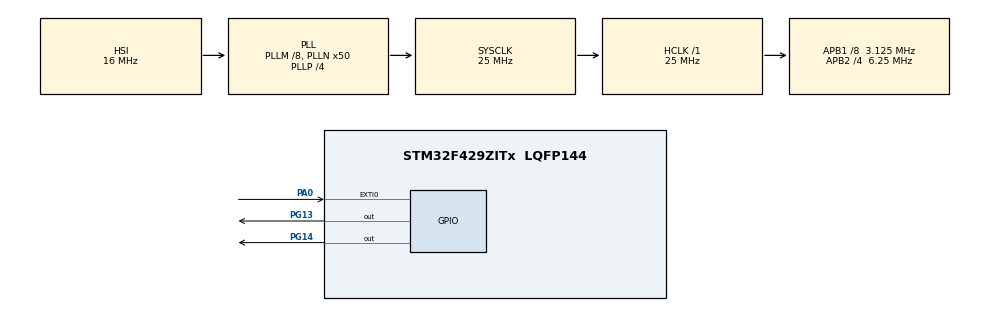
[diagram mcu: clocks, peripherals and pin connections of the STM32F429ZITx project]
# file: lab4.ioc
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Mcu.Family=STM32F4
Mcu.Name=STM32F429ZITx
Mcu.Package=LQFP144
NVIC.EXTI0_IRQn=true\:0\:0\:false\:false\:true\:true\:true\:true
NVIC.PriorityGroup=NVIC_PRIORITYGROUP_0
PA0/WKUP.GPIO_ModeDefaultEXTI=GPIO_MODE_IT_RISING_FALLING
PA0/WKUP.Signal=GPXTI0
PG13.Signal=GPIO_Output
PG14.Signal=GPIO_Output
ProjectManager.HeapSize=0x200
ProjectManager.StackSize=0x400
ProjectManager.TargetToolchain=Makefile
RCC.48MHZClocksFreq_Value=14285714.285714285
RCC.AHBFreq_Value=25000000
RCC.APB1CLKDivider=RCC_HCLK_DIV8
RCC.APB1Freq_Value=3125000
RCC.APB1TimFreq_Value=6250000
RCC.APB2CLKDivider=RCC_HCLK_DIV4
RCC.APB2Freq_Value=6250000
RCC.APB2TimFreq_Value=12500000
RCC.CortexFreq_Value=25000000
RCC.HCLKFreq_Value=25000000
RCC.HSE_VALUE=8000000
RCC.HSI_VALUE=16000000
RCC.LSE_VALUE=32768
RCC.PLLM=8
RCC.PLLN=50
RCC.PLLP=RCC_PLLP_DIV4
RCC.PLLQ=7
RCC.SYSCLKFreq_VALUE=25000000
RCC.SYSCLKSource=RCC_SYSCLKSOURCE_PLLCLK
RCC.VCOOutputFreq_Value=100000000
board=STM32F429I-DISC1

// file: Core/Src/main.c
/* USER CODE BEGIN Header */
/**
  ******************************************************************************
  * @file           : main.c
  * @brief          : Main program body
  ******************************************************************************
  * @attention
  *
  * Copyright (c) 2025 STMicroelectronics.
  * All rights reserved.
  *
  * This software is licensed under terms that can be found in the LICENSE file
  * in the root directory of this software component.
  * If no LICENSE file comes with this software, it is provided AS-IS.
  *
  ******************************************************************************
  */
/* USER CODE END Header */
#include "main.h"
#include "stm32f4xx_hal.h"
#include "stm32f4xx_hal_gpio.h"

/* USER CODE BEGIN PD */
#define FAST_SWITCHING 100
#define SLOW_SWITCHING 1000
/* USER CODE END PD */

void SystemClock_Config(void);
static void MX_GPIO_Init(void);
/* USER CODE BEGIN PFP */
int zad1_i=0;
int zad4_delay=1000;
int zad5_time=0;
int zad5_interval=0;
/* USER CODE END PFP */

/* USER CODE BEGIN 0 */
void zad1(){
  zad1_i++;
}
void zad2(){
  HAL_GPIO_TogglePin(GPIOG,GPIO_PIN_13);
}

void zad3(){
  //Changed in cube ide trigger
  if(HAL_GPIO_ReadPin(GPIOA,GPIO_PIN_0))
    HAL_GPIO_WritePin(GPIOG,GPIO_PIN_13, GPIO_PIN_SET);
  else
    HAL_GPIO_WritePin(GPIOG,GPIO_PIN_13, GPIO_PIN_RESET);
}

void zad4(){
  if(HAL_GPIO_ReadPin(GPIOA,GPIO_PIN_0) && zad4_delay == SLOW_SWITCHING)
    zad4_delay = FAST_SWITCHING;
  else if(HAL_GPIO_ReadPin(GPIOA,GPIO_PIN_0) && zad4_delay == FAST_SWITCHING)
    zad4_delay = SLOW_SWITCHING;
}

void zad5(){
  if(HAL_GPIO_ReadPin(GPIOA,GPIO_PIN_0)){
    zad5_interval = HAL_GetTick() - zad5_time;
    zad5_time = HAL_GetTick();
  }

}
void HAL_GPIO_EXTI_Callback(uint16_t GPIO_Pin){
   /*zad1();*/
  /*zad2();*/
  /*zad3();*/
  /*zad4();*/
  zad5();
}

/* USER CODE END 0 */

int main(void)
{

  /* MCU Configuration--------------------------------------------------------*/

  /* Reset of all peripherals, Initializes the Flash interface and the Systick. */
  HAL_Init();

  /* Configure the system clock */
  SystemClock_Config();

  /* Initialize all configured peripherals */
  MX_GPIO_Init();

  /* Infinite loop */
  /* USER CODE BEGIN WHILE */
  while (1)
  {
    HAL_GPIO_TogglePin(GPIOG,GPIO_PIN_14);
    HAL_Delay(zad4_delay);
    /* USER CODE END WHILE */

  }
}

void SystemClock_Config(void)
{
  RCC_OscInitTypeDef RCC_OscInitStruct = {0};
  RCC_ClkInitTypeDef RCC_ClkInitStruct = {0};

  /** Configure the main internal regulator output voltage
  */
  __HAL_RCC_PWR_CLK_ENABLE();
  __HAL_PWR_VOLTAGESCALING_CONFIG(PWR_REGULATOR_VOLTAGE_SCALE3);

  /** Initializes the RCC Oscillators according to the specified parameters
  * in the RCC_OscInitTypeDef structure.
  */
  RCC_OscInitStruct.OscillatorType = RCC_OSCILLATORTYPE_HSI;
  RCC_OscInitStruct.HSIState = RCC_HSI_ON;
  RCC_OscInitStruct.HSICalibrationValue = RCC_HSICALIBRATION_DEFAULT;
  RCC_OscInitStruct.PLL.PLLState = RCC_PLL_ON;
  RCC_OscInitStruct.PLL.PLLSource = RCC_PLLSOURCE_HSI;
  RCC_OscInitStruct.PLL.PLLM = 8;
  RCC_OscInitStruct.PLL.PLLN = 50;
  RCC_OscInitStruct.PLL.PLLP = RCC_PLLP_DIV4;
  RCC_OscInitStruct.PLL.PLLQ = 7;
  if (HAL_RCC_OscConfig(&RCC_OscInitStruct) != HAL_OK)
  {
    Error_Handler();
  }

  /** Initializes the CPU, AHB and APB buses clocks
  */
  RCC_ClkInitStruct.ClockType = RCC_CLOCKTYPE_HCLK|RCC_CLOCKTYPE_SYSCLK
                              |RCC_CLOCKTYPE_PCLK1|RCC_CLOCKTYPE_PCLK2;
  RCC_ClkInitStruct.SYSCLKSource = RCC_SYSCLKSOURCE_PLLCLK;
  RCC_ClkInitStruct.AHBCLKDivider = RCC_SYSCLK_DIV1;
  RCC_ClkInitStruct.APB1CLKDivider = RCC_HCLK_DIV8;
  RCC_ClkInitStruct.APB2CLKDivider = RCC_HCLK_DIV4;

  if (HAL_RCC_ClockConfig(&RCC_ClkInitStruct, FLASH_LATENCY_0) != HAL_OK)
  {
    Error_Handler();
  }
}

static void MX_GPIO_Init(void)
{
  GPIO_InitTypeDef GPIO_InitStruct = {0};

  /* GPIO Ports Clock Enable */
  __HAL_RCC_GPIOA_CLK_ENABLE();
  __HAL_RCC_GPIOG_CLK_ENABLE();

  /*Configure GPIO pin Output Level */
  HAL_GPIO_WritePin(GPIOG, GPIO_PIN_13|GPIO_PIN_14, GPIO_PIN_RESET);

  /*Configure GPIO pin : PA0 */
  GPIO_InitStruct.Pin = GPIO_PIN_0;
  GPIO_InitStruct.Mode = GPIO_MODE_IT_RISING_FALLING;
  GPIO_InitStruct.Pull = GPIO_NOPULL;
  HAL_GPIO_Init(GPIOA, &GPIO_InitStruct);

  /*Configure GPIO pins : PG13 PG14 */
  GPIO_InitStruct.Pin = GPIO_PIN_13|GPIO_PIN_14;
  GPIO_InitStruct.Mode = GPIO_MODE_OUTPUT_PP;
  GPIO_InitStruct.Pull = GPIO_NOPULL;
  GPIO_InitStruct.Speed = GPIO_SPEED_FREQ_LOW;
  HAL_GPIO_Init(GPIOG, &GPIO_InitStruct);

  /* EXTI interrupt init*/
  HAL_NVIC_SetPriority(EXTI0_IRQn, 0, 0);
  HAL_NVIC_EnableIRQ(EXTI0_IRQn);

}

void Error_Handler(void)
{
  __disable_irq();
  while (1)
  {
  }
}
